VERSION "highnoon_telemetry"

NS_ :

BS_:

BU_: TPEE_MPPT_C TPEE_MPPT_B TPEE_MPPT_A Telemetry Pump Pedals PDU LV_Carrier External Dashboard_Display BPS ChargerInterface Controls VCU Bosch_LWS Prohelion_WaveSculptor22 Vector__XXX

CM_ "Full HighNoon telemetry catalog: CarCAN + SteeringCAN + MotorCAN + telem_rev1 (DAQ/GPS).";
CM_ "TelemCAN messages use internal ID 0x1000 | physical 11-bit CAN ID.";

CM_ "source=CarCAN" BO_ 1;
BO_ 1 BPS_Status: 8 BPS
SG_ BPS_Fault : 0|8@1+ (1,0) [0|0] "" Vector__XXX
SG_ BPS_Charge_OK : 8|1@1+ (1,0) [0|0] "" Vector__XXX
SG_ BPS_Regen_OK : 9|1@1+ (1,0) [0|0] "" Vector__XXX
SG_ HV_Plus_Contactor_State : 10|1@1+ (1,0) [0|0] "" Vector__XXX
SG_ HV_Minus_Contactor_State : 11|1@1+ (1,0) [0|0] "" Vector__XXX
SG_ Array_Contactor_State : 12|1@1+ (1,0) [0|0] "" Vector__XXX
SG_ Array_Precharge_Contactor_State : 13|1@1+ (1,0) [0|0] "" Vector__XXX
SG_ Main_Battery_Voltage : 16|24@1+ (0.001,0) [0|16777.215] "V" Vector__XXX
SG_ Main_Battery_Avg_Temperature : 40|16@1- (0.01,0) [-327.68|327.67] "°C" Vector__XXX
SG_ BPS_Segment0_Status : 56|1@1+ (1,0) [0|0] "" Vector__XXX
SG_ BPS_Segment1_Status : 57|1@1+ (1,0) [0|0] "" Vector__XXX
SG_ BPS_Segment2_Status : 58|1@1+ (1,0) [0|0] "" Vector__XXX
SG_ BPS_Segment3_Status : 59|1@1+ (1,0) [0|0] "" Vector__XXX
SG_ BPS_Segment4_Status : 60|1@1+ (1,0) [0|0] "" Vector__XXX
SG_ BPS_Segment5_Status : 61|1@1+ (1,0) [0|0] "" Vector__XXX
SG_ BPS_Segment6_Status : 62|1@1+ (1,0) [0|0] "" Vector__XXX
SG_ BPS_Segment7_Status : 63|1@1+ (1,0) [0|0] "" Vector__XXX

CM_ "source=CarCAN" BO_ 11;
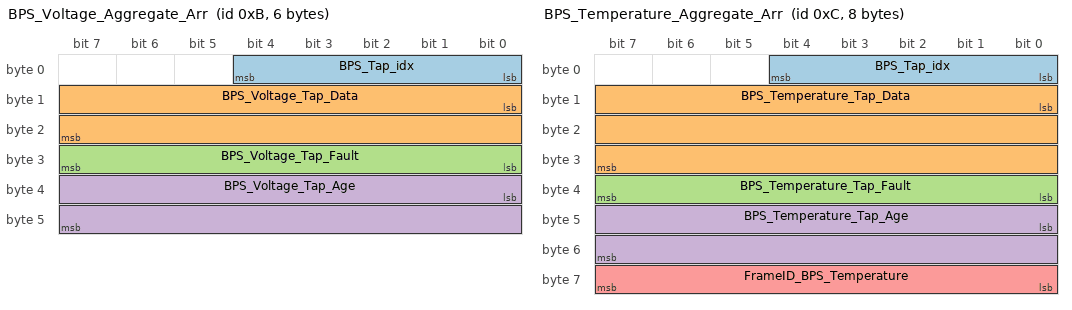
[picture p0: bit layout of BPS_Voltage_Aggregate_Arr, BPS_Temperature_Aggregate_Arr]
BO_ 11 BPS_Voltage_Aggregate_Arr: 6 BPS
SG_ BPS_Tap_idx : 0|5@1+ (1,0) [0|31] "" Vector__XXX
SG_ BPS_Voltage_Tap_Data : 8|16@1+ (0.001,0) [0|65.535] "V" Vector__XXX
SG_ BPS_Voltage_Tap_Fault : 24|8@1+ (1,0) [0|0] "" Vector__XXX
SG_ BPS_Voltage_Tap_Age : 32|16@1+ (1,0) [0|65535] "ms" Vector__XXX

CM_ "source=CarCAN" BO_ 12;
BO_ 12 BPS_Temperature_Aggregate_Arr: 8 BPS
SG_ BPS_Tap_idx : 0|5@1+ (1,0) [0|31] "" Vector__XXX
SG_ BPS_Temperature_Tap_Data : 8|24@1- (0.001,0) [-8388.608|8388.607] "°C" Vector__XXX
SG_ BPS_Temperature_Tap_Fault : 32|8@1+ (1,0) [0|255] "" Vector__XXX
SG_ BPS_Temperature_Tap_Age : 40|16@1+ (1,0) [0|65535] "ms" Vector__XXX
SG_ FrameID_BPS_Temperature : 56|8@1+ (1,0) [0|255] "" Vector__XXX

CM_ "source=CarCAN" BO_ 14;
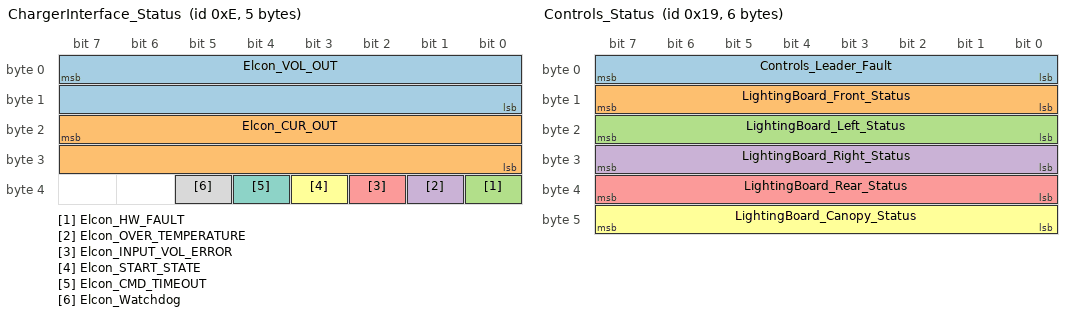
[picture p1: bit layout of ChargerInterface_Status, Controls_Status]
BO_ 14 ChargerInterface_Status: 5 ChargerInterface
SG_ Elcon_VOL_OUT : 7|16@0+ (0.1,0) [0|6553.5] "V" Vector__XXX
SG_ Elcon_CUR_OUT : 23|16@0+ (0.1,0) [0|6553.5] "A" Vector__XXX
SG_ Elcon_HW_FAULT : 32|1@0+ (1,0) [0|1] "" Vector__XXX
SG_ Elcon_OVER_TEMPERATURE : 33|1@0+ (1,0) [0|1] "" Vector__XXX
SG_ Elcon_INPUT_VOL_ERROR : 34|1@0+ (1,0) [0|1] "" Vector__XXX
SG_ Elcon_START_STATE : 35|1@0+ (1,0) [0|1] "" Vector__XXX
SG_ Elcon_CMD_TIMEOUT : 36|1@0+ (1,0) [0|1] "" Vector__XXX
SG_ Elcon_Watchdog : 37|1@0+ (1,0) [0|1] "" Vector__XXX

CM_ "source=CarCAN" BO_ 15;
BO_ 15 BPS_Fault_Val_Arr: 6 BPS
SG_ BPS_Tap_idx : 0|5@1+ (1,0) [0|31] "" Vector__XXX
SG_ BPS_Voltage_Tap_Data : 8|16@1+ (0.001,0) [0|65.535] "V" Vector__XXX
SG_ BPS_Temperature_Tap_Data : 24|24@1- (0.001,0) [-8388.608|8388.607] "°C" Vector__XXX

CM_ "source=CarCAN" BO_ 24;
BO_ 24 VCU_Status: 6 VCU
SG_ VCU_FSM_State : 0|4@1+ (1,0) [0|15] "" Vector__XXX
SG_ Motor_Ready : 4|1@1+ (1,0) [0|0] "" Vector__XXX
SG_ Motor_Precharge_Contactor_State : 5|1@1+ (1,0) [0|0] "" Vector__XXX
SG_ Motor_Contactor_State : 6|1@1+ (1,0) [0|0] "" Vector__XXX
SG_ VCU_Driver_Input_Watchdog : 7|1@1+ (1,0) [0|0] "" Vector__XXX
SG_ VCU_Pedals_Watchdog : 8|1@1+ (1,0) [0|0] "" Vector__XXX
SG_ VCU_BPS_Watchdog : 9|1@1+ (1,0) [0|0] "" Vector__XXX
SG_ VCU_Steering_Angle_Watchdog : 10|1@1+ (1,0) [0|1] "" Vector__XXX
SG_ VCU_BPS_FAULT_DETECTED : 11|1@1+ (1,0) [0|1] "" Vector__XXX
SG_ VCU_CONTROLS_FAULT_DETECTED : 12|1@1+ (1,0) [0|1] "" Vector__XXX
SG_ VCU_MTR_FAULT_DETECTED : 13|1@1+ (1,0) [0|1] "" Vector__XXX
SG_ VCU_PEDALS_FAULT_DETECTED : 14|1@1+ (1,0) [0|1] "" Vector__XXX
SG_ VCU_STEERING_FAULT_DETECTED : 15|1@1+ (1,0) [0|1] "" Vector__XXX
SG_ VCU_MotorCommandSource : 16|1@1+ (1,0) [0|1] "" Vector__XXX
SG_ VCU_Regen_Active : 17|1@1+ (1,0) [0|0] "" Vector__XXX
SG_ VCU_Regen_OK : 18|1@1+ (1,0) [0|0] "" Vector__XXX
SG_ VCU_MTR_PCHG_TIMEOUT : 19|1@1+ (1,0) [0|1] "" Vector__XXX
SG_ VCU_MTR_PCHG_CONT_TIMEOUT : 20|1@1+ (1,0) [0|1] "" Vector__XXX
SG_ VCU_MTR_PCHG_CONT_MISMATCH : 21|1@1+ (1,0) [0|1] "" Vector__XXX
SG_ VCU_MTR_CONT_MISMATCH : 22|1@1+ (1,0) [0|1] "" Vector__XXX
SG_ VCU_MTR_CONT_TIMEOUT : 23|1@1+ (1,0) [0|1] "" Vector__XXX
SG_ VCU_PCHG_OV : 24|1@1+ (1,0) [0|1] "" Vector__XXX
SG_ VCU_PCHG_UV : 25|1@1+ (1,0) [0|1] "" Vector__XXX
SG_ VCU_MTR_OV : 26|1@1+ (1,0) [0|1] "" Vector__XXX
SG_ VCU_MTR_UV : 27|1@1+ (1,0) [0|1] "" Vector__XXX
SG_ VCU_OTHER_FAULT : 28|1@1+ (1,0) [0|1] "" Vector__XXX
SG_ VCU_MTR_DIR_CHANGE_LOCKOUT : 29|1@1+ (1,0) [0|1] "" Vector__XXX
SG_ VCU_TIPPING_WARNING : 30|1@1+ (1,0) [0|1] "" Vector__XXX
SG_ VCU_WARN_REGEN_NOT_ALLOW : 31|1@1+ (1,0) [0|1] "" Vector__XXX
SG_ VCU_WARN_REGEN_NOT_EN : 32|1@1+ (1,0) [0|1] "" Vector__XXX
SG_ VCU_FSM_INP_BRAKE : 33|1@1+ (1,0) [0|1] "" Vector__XXX
SG_ VCU_FSM_INP_PCHG_OK : 34|1@1+ (1,0) [0|1] "" Vector__XXX
SG_ VCU_FSM_INP_CRUISE_REQ : 35|1@1+ (1,0) [0|1] "" Vector__XXX
SG_ VCU_FSM_INP_REGEN_REQ : 36|1@1+ (1,0) [0|1] "" Vector__XXX
SG_ VCU_FSM_INP_REGEN_ENABLE : 37|1@1+ (1,0) [0|1] "" Vector__XXX
SG_ VCU_FSM_INP_REGEN_RDY : 38|1@1+ (1,0) [0|1] "" Vector__XXX
SG_ VCU_FSM_INP_FORWARD : 39|1@1+ (1,0) [0|1] "" Vector__XXX
SG_ VCU_FSM_INP_NEUTRAL : 40|1@1+ (1,0) [0|1] "" Vector__XXX
SG_ VCU_FSM_INP_REVERSE : 41|1@1+ (1,0) [0|1] "" Vector__XXX

CM_ "source=CarCAN" BO_ 25;
BO_ 25 Controls_Status: 6 Controls
SG_ Controls_Leader_Fault : 0|8@1+ (1,0) [0|0] "" Vector__XXX
SG_ LightingBoard_Front_Status : 8|8@1+ (1,0) [0|0] "" Vector__XXX
SG_ LightingBoard_Left_Status : 16|8@1+ (1,0) [0|0] "" Vector__XXX
SG_ LightingBoard_Right_Status : 24|8@1+ (1,0) [0|0] "" Vector__XXX
SG_ LightingBoard_Rear_Status : 32|8@1+ (1,0) [0|0] "" Vector__XXX
SG_ LightingBoard_Canopy_Status : 40|8@1+ (1,0) [0|0] "" Vector__XXX

CM_ "source=CarCAN" BO_ 32;
BO_ 32 BPS_Precharge_Voltages: 6 BPS
SG_ BPS_Precharge_Battery_Voltage : 0|24@1+ (0.001,0) [0|16777.215] "V" Vector__XXX
SG_ BPS_Precharge_Array_Voltage : 24|24@1+ (0.001,0) [0|16777.215] "V" Vector__XXX

CM_ "source=CarCAN" BO_ 33;
BO_ 33 VCU_Precharge_Voltages: 6 VCU
SG_ VCU_Precharge_Battery_Voltage : 0|24@1+ (0.001,0) [0|16777.215] "V" Vector__XXX
SG_ VCU_Precharge_Motor_Voltage : 24|24@1+ (0.001,0) [0|16777.215] "V" Vector__XXX

CM_ "source=CarCAN" BO_ 80;
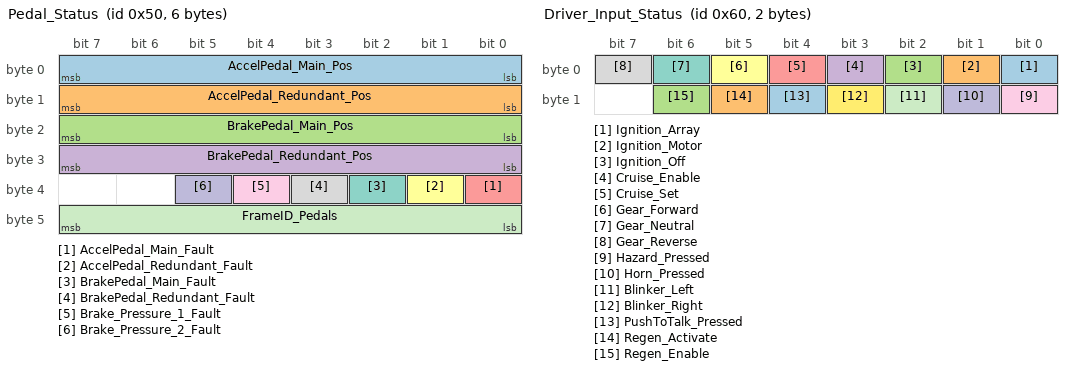
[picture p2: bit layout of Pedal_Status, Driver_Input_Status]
BO_ 80 Pedal_Status: 6 Pedals
SG_ AccelPedal_Main_Pos : 0|8@1+ (1,0) [0|100] "%"  VCU
SG_ AccelPedal_Redundant_Pos : 8|8@1+ (1,0) [0|100] "%"  VCU
SG_ BrakePedal_Main_Pos : 16|8@1+ (1,0) [0|100] "%"  VCU
SG_ BrakePedal_Redundant_Pos : 24|8@1+ (1,0) [0|100] "%"  VCU
SG_ AccelPedal_Main_Fault : 32|1@1+ (1,0) [0|0] ""  VCU
SG_ AccelPedal_Redundant_Fault : 33|1@1+ (1,0) [0|0] ""  VCU
SG_ BrakePedal_Main_Fault : 34|1@1+ (1,0) [0|0] ""  VCU
SG_ BrakePedal_Redundant_Fault : 35|1@1+ (1,0) [0|0] ""  VCU
SG_ Brake_Pressure_1_Fault : 36|1@1+ (1,0) [0|0] "" Vector__XXX
SG_ Brake_Pressure_2_Fault : 37|1@1+ (1,0) [0|0] "" Vector__XXX
SG_ FrameID_Pedals : 40|8@1+ (1,0) [0|255] "" Vector__XXX

CM_ "source=CarCAN" BO_ 96;
BO_ 96 Driver_Input_Status: 2 Controls
SG_ Ignition_Array : 0|1@1+ (1,0) [0|0] ""  VCU
SG_ Ignition_Motor : 1|1@1+ (1,0) [0|0] ""  VCU
SG_ Ignition_Off : 2|1@1+ (1,0) [0|0] ""  VCU
SG_ Cruise_Enable : 3|1@1+ (1,0) [0|0] ""  VCU
SG_ Cruise_Set : 4|1@1+ (1,0) [0|0] ""  VCU
SG_ Gear_Forward : 5|1@1+ (1,0) [0|0] ""  VCU
SG_ Gear_Neutral : 6|1@1+ (1,0) [0|0] ""  VCU
SG_ Gear_Reverse : 7|1@1+ (1,0) [0|0] ""  VCU
SG_ Hazard_Pressed : 8|1@1+ (1,0) [0|0] "" Vector__XXX
SG_ Horn_Pressed : 9|1@1+ (1,0) [0|0] "" Vector__XXX
SG_ Blinker_Left : 10|1@1+ (1,0) [0|0] "" Vector__XXX
SG_ Blinker_Right : 11|1@1+ (1,0) [0|0] "" Vector__XXX
SG_ PushToTalk_Pressed : 12|1@1+ (1,0) [0|0] "" Vector__XXX
SG_ Regen_Activate : 13|1@1+ (1,0) [0|0] ""  VCU
SG_ Regen_Enable : 14|1@1+ (1,0) [0|0] ""  VCU

CM_ "source=CarCAN" BO_ 103;
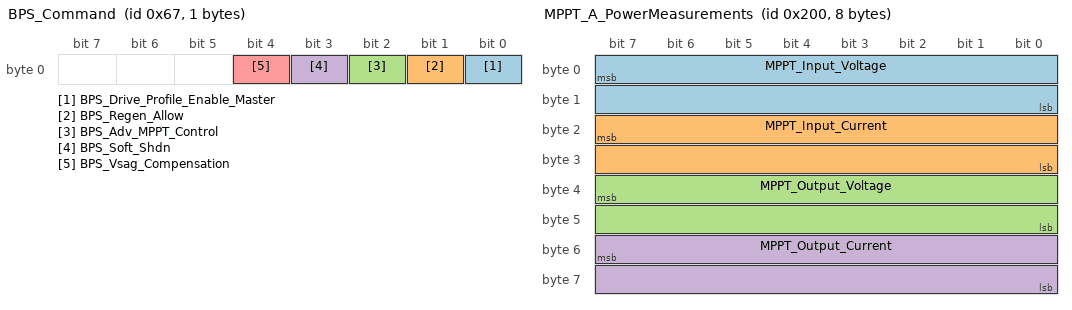
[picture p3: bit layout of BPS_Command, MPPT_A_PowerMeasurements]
BO_ 103 BPS_Command: 1 Controls
SG_ BPS_Drive_Profile_Enable_Master : 0|1@1+ (1,0) [0|1] "" Vector__XXX
SG_ BPS_Regen_Allow : 1|1@1+ (1,0) [0|1] "" Vector__XXX
SG_ BPS_Adv_MPPT_Control : 2|1@1+ (1,0) [0|1] "" Vector__XXX
SG_ BPS_Soft_Shdn : 3|1@1+ (1,0) [0|1] "" Vector__XXX
SG_ BPS_Vsag_Compensation : 4|1@1+ (1,0) [0|1] "" Vector__XXX

CM_ "source=CarCAN" BO_ 105;
BO_ 105 BPS_Module_Override: 8 Controls
SG_ Module0_Override : 0|2@1+ (1,0) [0|3] "" Vector__XXX
SG_ Module1_Override : 2|2@1+ (1,0) [0|3] "" Vector__XXX
SG_ Module2_Override : 4|2@1+ (1,0) [0|3] "" Vector__XXX
SG_ Module3_Override : 6|2@1+ (1,0) [0|3] "" Vector__XXX
SG_ Module4_Override : 8|2@1+ (1,0) [0|3] "" Vector__XXX
SG_ Module5_Override : 10|2@1+ (1,0) [0|3] "" Vector__XXX
SG_ Module6_Override : 12|2@1+ (1,0) [0|3] "" Vector__XXX
SG_ Module7_Override : 14|2@1+ (1,0) [0|3] "" Vector__XXX
SG_ Module8_Override : 16|2@1+ (1,0) [0|3] "" Vector__XXX
SG_ Module9_Override : 18|2@1+ (1,0) [0|3] "" Vector__XXX
SG_ Module10_Override : 20|2@1+ (1,0) [0|3] "" Vector__XXX
SG_ Module11_Override : 22|2@1+ (1,0) [0|3] "" Vector__XXX
SG_ Module12_Override : 24|2@1+ (1,0) [0|3] "" Vector__XXX
SG_ Module13_Override : 26|2@1+ (1,0) [0|3] "" Vector__XXX
SG_ Module14_Override : 28|2@1+ (1,0) [0|3] "" Vector__XXX
SG_ Module15_Override : 30|2@1+ (1,0) [0|3] "" Vector__XXX
SG_ Module16_Override : 32|2@1+ (1,0) [0|3] "" Vector__XXX
SG_ Module17_Override : 34|2@1+ (1,0) [0|3] "" Vector__XXX
SG_ Module18_Override : 36|2@1+ (1,0) [0|3] "" Vector__XXX
SG_ Module19_Override : 38|2@1+ (1,0) [0|3] "" Vector__XXX
SG_ Module20_Override : 40|2@1+ (1,0) [0|3] "" Vector__XXX
SG_ Module21_Override : 42|2@1+ (1,0) [0|3] "" Vector__XXX
SG_ Module22_Override : 44|2@1+ (1,0) [0|3] "" Vector__XXX
SG_ Module23_Override : 46|2@1+ (1,0) [0|3] "" Vector__XXX
SG_ Module24_Override : 48|2@1+ (1,0) [0|3] "" Vector__XXX
SG_ Module25_Override : 50|2@1+ (1,0) [0|3] "" Vector__XXX
SG_ Module26_Override : 52|2@1+ (1,0) [0|3] "" Vector__XXX
SG_ Module27_Override : 54|2@1+ (1,0) [0|3] "" Vector__XXX
SG_ Module28_Override : 56|2@1+ (1,0) [0|3] "" Vector__XXX
SG_ Module29_Override : 58|2@1+ (1,0) [0|3] "" Vector__XXX
SG_ Module30_Override : 60|2@1+ (1,0) [0|3] "" Vector__XXX
SG_ Module31_Override : 62|2@1+ (1,0) [0|3] "" Vector__XXX

CM_ "source=CarCAN" BO_ 512;
BO_ 512 MPPT_A_PowerMeasurements: 8 TPEE_MPPT_A
SG_ MPPT_Input_Voltage : 7|16@0- (0.01,0) [-327.68|327.67] "V" Vector__XXX
SG_ MPPT_Input_Current : 23|16@0- (0.0005,0) [-16.384|16.3835] "A" Vector__XXX
SG_ MPPT_Output_Voltage : 39|16@0- (0.01,0) [-327.68|327.67] "V" Vector__XXX
SG_ MPPT_Output_Current : 55|16@0- (0.0005,0) [-16.384|16.3835] "A" Vector__XXX

CM_ "source=CarCAN" BO_ 513;
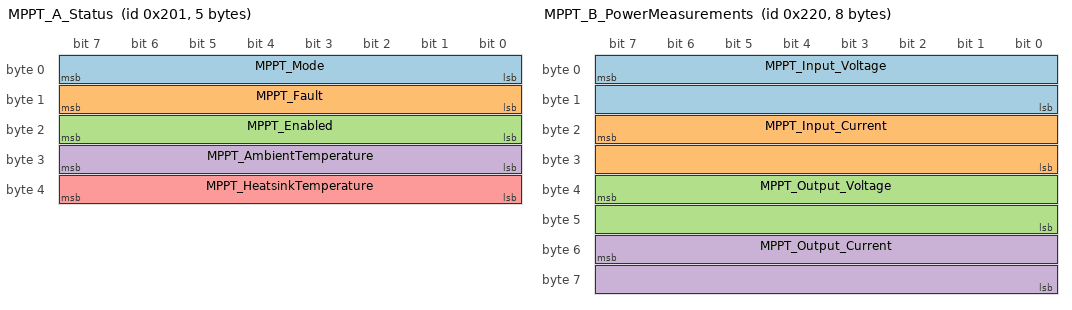
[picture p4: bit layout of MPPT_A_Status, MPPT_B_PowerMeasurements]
BO_ 513 MPPT_A_Status: 5 TPEE_MPPT_A
SG_ MPPT_Mode : 7|8@0+ (1,0) [0|0] "" Vector__XXX
SG_ MPPT_Fault : 15|8@0+ (1,0) [0|0] "" Vector__XXX
SG_ MPPT_Enabled : 23|8@0- (1,0) [0|2] "" Vector__XXX
SG_ MPPT_AmbientTemperature : 31|8@0- (1,0) [-128|127] "°C" Vector__XXX
SG_ MPPT_HeatsinkTemperature : 39|8@0- (1,0) [-128|127] "°C" Vector__XXX

CM_ "source=CarCAN" BO_ 514;
BO_ 514 MPPT_A_SweepMeasurements: 6 TPEE_MPPT_A
SG_ MPPT_Sweep_Data_cnt : 7|8@0+ (1,0) [0|127] "" Vector__XXX
SG_ MPPT_Sweep_Data_Current : 23|16@0- (0.0005,0) [-16.384|16.3835] "A" Vector__XXX
SG_ MPPT_Sweep_Data_Voltage : 39|16@0- (0.01,0) [-327.68|327.67] "V" Vector__XXX

CM_ "source=CarCAN" BO_ 521;
BO_ 521 MPPT_A_SetMode: 1 BPS
SG_ MPPT_Set_Enable : 7|8@0+ (1,0) [0|2] ""  TPEE_MPPT_A

CM_ "source=CarCAN" BO_ 528;
BO_ 528 MPPT_A_PerformSweep: 5 External
SG_ MPPT_Set_Sweep_Start : 7|16@0- (0.01,0) [-327.68|327.67] "V" Vector__XXX
SG_ MPPT_Set_Sweep_End : 23|16@0- (0.0005,0) [-16.384|16.3835] "A" Vector__XXX
SG_ MPPT_Set_Sweep_Size : 39|8@0+ (1,0) [4|128] "" Vector__XXX

CM_ "source=CarCAN" BO_ 529;
BO_ 529 MPPT_A_SetOutputVoltageLimit: 2 BPS
SG_ MPPT_SetOutputVoltageLimit : 7|16@0- (0.01,0) [-327.68|327.67] "V" Vector__XXX

CM_ "source=CarCAN" BO_ 530;
BO_ 530 MPPT_A_SetOutputCurrentLimit: 2 BPS
SG_ MPPT_SetOutputCurrentLimit : 7|16@0- (0.0005,0) [-16.384|16.3835] "A" Vector__XXX

CM_ "source=CarCAN" BO_ 544;
BO_ 544 MPPT_B_PowerMeasurements: 8 TPEE_MPPT_B
SG_ MPPT_Input_Voltage : 7|16@0- (0.01,0) [-327.68|327.67] "V" Vector__XXX
SG_ MPPT_Input_Current : 23|16@0- (0.0005,0) [-16.384|16.3835] "A" Vector__XXX
SG_ MPPT_Output_Voltage : 39|16@0- (0.01,0) [-327.68|327.67] "V" Vector__XXX
SG_ MPPT_Output_Current : 55|16@0- (0.0005,0) [-16.384|16.3835] "A" Vector__XXX

CM_ "source=CarCAN" BO_ 545;
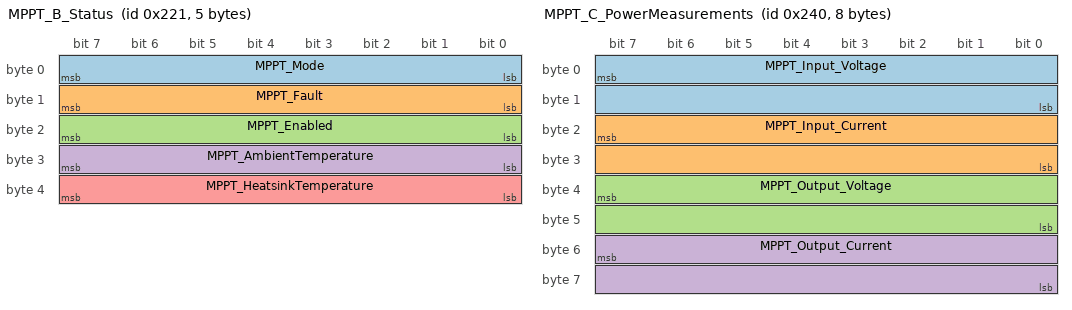
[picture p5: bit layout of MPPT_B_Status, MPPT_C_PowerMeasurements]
BO_ 545 MPPT_B_Status: 5 TPEE_MPPT_B
SG_ MPPT_Mode : 7|8@0+ (1,0) [0|0] "" Vector__XXX
SG_ MPPT_Fault : 15|8@0+ (1,0) [0|0] "" Vector__XXX
SG_ MPPT_Enabled : 23|8@0- (1,0) [0|2] "" Vector__XXX
SG_ MPPT_AmbientTemperature : 31|8@0- (1,0) [-128|127] "°C" Vector__XXX
SG_ MPPT_HeatsinkTemperature : 39|8@0- (1,0) [-128|127] "°C" Vector__XXX

CM_ "source=CarCAN" BO_ 546;
BO_ 546 MPPT_B_SweepMeasurements: 6 TPEE_MPPT_B
SG_ MPPT_Sweep_Data_cnt : 7|8@0+ (1,0) [0|127] "" Vector__XXX
SG_ MPPT_Sweep_Data_Current : 23|16@0- (0.0005,0) [-16.384|16.3835] "A" Vector__XXX
SG_ MPPT_Sweep_Data_Voltage : 39|16@0- (0.01,0) [-327.68|327.67] "V" Vector__XXX

CM_ "source=CarCAN" BO_ 553;
BO_ 553 MPPT_B_SetMode: 1 BPS
SG_ MPPT_Set_Enable : 7|8@0+ (1,0) [0|2] "" Vector__XXX

CM_ "source=CarCAN" BO_ 560;
BO_ 560 MPPT_B_PerformSweep: 5 External
SG_ MPPT_Set_Sweep_Start : 7|16@0- (0.01,0) [-327.68|327.67] "V" Vector__XXX
SG_ MPPT_Set_Sweep_End : 23|16@0- (0.0005,0) [-16.384|16.3835] "A" Vector__XXX
SG_ MPPT_Set_Sweep_Size : 39|8@0+ (1,0) [4|128] "" Vector__XXX

CM_ "source=CarCAN" BO_ 561;
BO_ 561 MPPT_B_SetOutputVoltageLimit: 2 BPS
SG_ MPPT_SetOutputVoltageLimit : 7|16@0- (0.01,0) [-327.68|327.67] "V" Vector__XXX

CM_ "source=CarCAN" BO_ 562;
BO_ 562 MPPT_B_SetOutputCurrentLimit: 2 BPS
SG_ MPPT_SetOutputCurrentLimit : 7|16@0- (0.0005,0) [-16.384|16.3835] "A" Vector__XXX

CM_ "source=CarCAN" BO_ 576;
BO_ 576 MPPT_C_PowerMeasurements: 8 TPEE_MPPT_C
SG_ MPPT_Input_Voltage : 7|16@0- (0.01,0) [-327.68|327.67] "V" Vector__XXX
SG_ MPPT_Input_Current : 23|16@0- (0.0005,0) [-16.384|16.3835] "A" Vector__XXX
SG_ MPPT_Output_Voltage : 39|16@0- (0.01,0) [-327.68|327.67] "V" Vector__XXX
SG_ MPPT_Output_Current : 55|16@0- (0.0005,0) [-16.384|16.3835] "A" Vector__XXX

CM_ "source=CarCAN" BO_ 577;
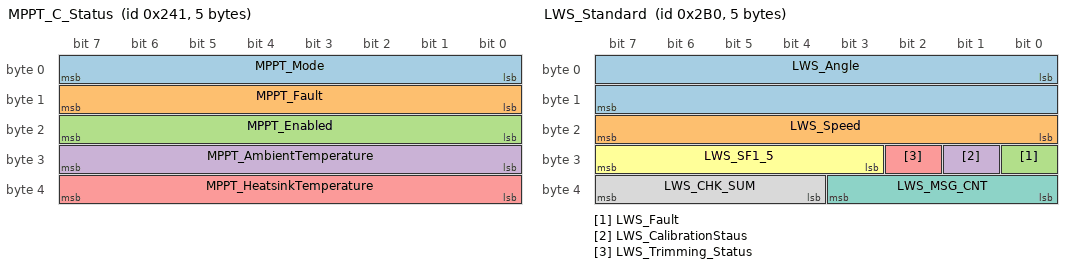
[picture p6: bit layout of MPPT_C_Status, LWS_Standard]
BO_ 577 MPPT_C_Status: 5 TPEE_MPPT_C
SG_ MPPT_Mode : 7|8@0+ (1,0) [0|0] "" Vector__XXX
SG_ MPPT_Fault : 15|8@0+ (1,0) [0|0] "" Vector__XXX
SG_ MPPT_Enabled : 23|8@0- (1,0) [0|2] "" Vector__XXX
SG_ MPPT_AmbientTemperature : 31|8@0- (1,0) [-128|127] "°C" Vector__XXX
SG_ MPPT_HeatsinkTemperature : 39|8@0- (1,0) [-128|127] "°C" Vector__XXX

CM_ "source=CarCAN" BO_ 578;
BO_ 578 MPPT_C_SweepMeasurements: 6 TPEE_MPPT_C
SG_ MPPT_Sweep_Data_cnt : 7|8@0+ (1,0) [0|127] "" Vector__XXX
SG_ MPPT_Sweep_Data_Current : 23|16@0- (0.0005,0) [-16.384|16.3835] "A" Vector__XXX
SG_ MPPT_Sweep_Data_Voltage : 39|16@0- (0.01,0) [-327.68|327.67] "V" Vector__XXX

CM_ "source=CarCAN" BO_ 585;
BO_ 585 MPPT_C_SetMode: 1 BPS
SG_ MPPT_Set_Enable : 7|8@0+ (1,0) [0|2] "" Vector__XXX

CM_ "source=CarCAN" BO_ 592;
BO_ 592 MPPT_C_PerformSweep: 5 External
SG_ MPPT_Set_Sweep_Start : 7|16@0- (0.01,0) [-327.68|327.67] "V" Vector__XXX
SG_ MPPT_Set_Sweep_End : 23|16@0- (0.0005,0) [-16.384|16.3835] "A" Vector__XXX
SG_ MPPT_Set_Sweep_Size : 39|8@0+ (1,0) [4|128] "" Vector__XXX

CM_ "source=CarCAN" BO_ 593;
BO_ 593 MPPT_C_SetOutputVoltageLimit: 2 BPS
SG_ MPPT_SetOutputVoltageLimit : 7|16@0- (0.01,0) [-327.68|327.67] "V" Vector__XXX

CM_ "source=CarCAN" BO_ 594;
BO_ 594 MPPT_C_SetOutputCurrentLimit: 2 BPS
SG_ MPPT_SetOutputCurrentLimit : 7|16@0- (0.0005,0) [-16.384|16.3835] "A" Vector__XXX

CM_ "source=SteeringCAN" BO_ 688;
BO_ 688 LWS_Standard: 5 Bosch_LWS
SG_ LWS_Angle : 0|16@1- (0.1,0) [-780|780] "°" Vector__XXX
SG_ LWS_Speed : 16|8@1+ (4,0) [0|1016] "°/s" Vector__XXX
SG_ LWS_Fault : 24|1@1+ (1,0) [0|1] "" Vector__XXX
SG_ LWS_CalibrationStaus : 25|1@1+ (1,0) [0|1] "" Vector__XXX
SG_ LWS_Trimming_Status : 26|1@1+ (1,0) [0|1] "" Vector__XXX
SG_ LWS_SF1_5 : 27|5@1+ (1,0) [0|31] "" Vector__XXX
SG_ LWS_MSG_CNT : 32|4@1+ (1,0) [0|15] "" Vector__XXX
SG_ LWS_CHK_SUM : 36|4@1+ (1,0) [0|15] "" Vector__XXX

CM_ "source=CarCAN" BO_ 768;
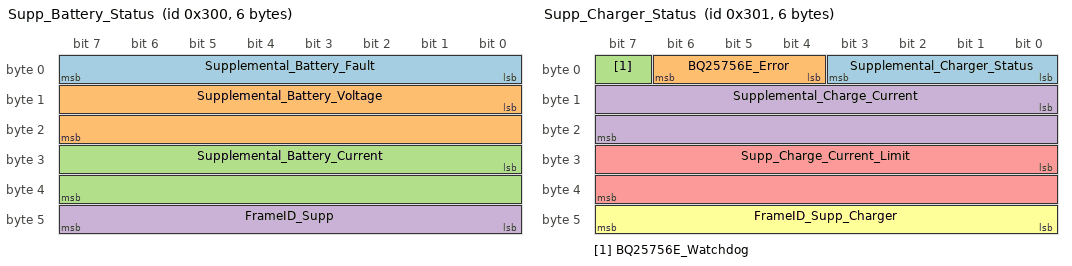
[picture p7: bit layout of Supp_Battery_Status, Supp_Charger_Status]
BO_ 768 Supp_Battery_Status: 6 LV_Carrier
SG_ Supplemental_Battery_Fault : 0|8@1+ (1,0) [0|255] "" Vector__XXX
SG_ Supplemental_Battery_Voltage : 8|16@1+ (0.001,0) [0|30] "V" Vector__XXX
SG_ Supplemental_Battery_Current : 24|16@1- (0.001,0) [-32.768|32.767] "A" Vector__XXX
SG_ FrameID_Supp : 40|8@1+ (1,0) [0|255] "" Vector__XXX

CM_ "source=CarCAN" BO_ 769;
BO_ 769 Supp_Charger_Status: 6 LV_Carrier
SG_ Supplemental_Charger_Status : 0|4@1+ (1,0) [0|15] "" Vector__XXX
SG_ BQ25756E_Error : 4|3@1+ (1,0) [0|7] "" Vector__XXX
SG_ BQ25756E_Watchdog : 7|1@1+ (1,0) [0|1] "" Vector__XXX
SG_ Supplemental_Charge_Current : 8|16@1- (0.001,0) [-32.768|32.767] "A" Vector__XXX
SG_ Supp_Charge_Current_Limit : 24|16@1+ (1,0) [0|65535] "mA" Vector__XXX
SG_ FrameID_Supp_Charger : 40|8@1+ (1,0) [0|255] "" Vector__XXX

CM_ "source=CarCAN" BO_ 770;
BO_ 770 Supp_Vicor_Stats: 5 LV_Carrier
SG_ Supplemental_Vicor_Voltage : 0|16@1+ (0.001,0) [0|65.535] "V" Vector__XXX
SG_ Supplemental_Vicor_Current : 16|16@1- (0.001,0) [-32.768|32.767] "A" Vector__XXX
SG_ FrameID_Supp_Charger : 32|8@1+ (1,0) [0|255] "" Vector__XXX

CM_ "source=CarCAN" BO_ 848;
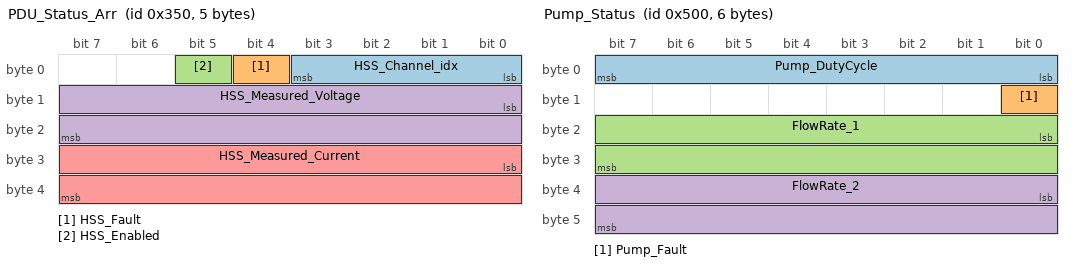
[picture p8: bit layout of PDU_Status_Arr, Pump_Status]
BO_ 848 PDU_Status_Arr: 5 PDU
SG_ HSS_Channel_idx : 0|4@1+ (1,0) [0|16] "" Vector__XXX
SG_ HSS_Fault : 4|1@1+ (1,0) [0|0] "" Vector__XXX
SG_ HSS_Enabled : 5|1@1+ (1,0) [0|0] "" Vector__XXX
SG_ HSS_Measured_Voltage : 8|16@1+ (0.001,0) [0|65.535] "V" Vector__XXX
SG_ HSS_Measured_Current : 24|16@1+ (0.001,0) [0|65.535] "A" Vector__XXX

CM_ "source=CarCAN" BO_ 849;
BO_ 849 PDU_Set_Switch_Arr: 1 VCU
SG_ HSS_Channel_idx : 0|4@1+ (1,0) [0|16] "" Vector__XXX
SG_ HSS_SetSwitch : 4|2@1+ (1,0) [0|0] ""  PDU

CM_ "source=CarCAN" BO_ 850;
BO_ 850 PDU_Set_Current_Limit_Arr: 3 VCU
SG_ HSS_Channel_idx : 0|4@1+ (1,0) [0|16] "" Vector__XXX
SG_ HSS_Current_Limit : 8|16@1+ (0.001,0) [0|8] "A"  PDU

CM_ "source=MotorCAN" BO_ 1025;
BO_ 1025 MC_DriveCommand: 8 VCU
SG_ MC_MotorVelocitySetpoint : 0|32@1- (1,0) [0|12000] "rpm"  Prohelion_WaveSculptor22
SG_ MC_MotorCurrentSetpoint : 32|32@1- (1,0) [0|1] "%"  Prohelion_WaveSculptor22

CM_ "source=MotorCAN" BO_ 1026;
BO_ 1026 MC_PowerCommand: 4 VCU
SG_ MC_MotorPowerSetpoint : 0|32@1- (1,0) [0|1] "%"  Prohelion_WaveSculptor22

CM_ "source=MotorCAN" BO_ 1027;
BO_ 1027 MC_ResetCommand: 1 VCU
SG_ MC_Reset : 0|8@1+ (1,0) [0|0] "" Vector__XXX

CM_ "source=MotorCAN" BO_ 1056;
BO_ 1056 MC_Info: 8 Prohelion_WaveSculptor22
SG_ MC_TritiumID : 0|32@1+ (1,0) [0|0] "" Vector__XXX
SG_ MC_SerialNumber : 32|32@1+ (1,0) [0|0] "" Vector__XXX

CM_ "source=MotorCAN" BO_ 1057;
BO_ 1057 MC_Status: 8 Prohelion_WaveSculptor22
SG_ MC_LIMIT_OutputVoltagePWM : 0|1@1+ (1,0) [0|1] "" Vector__XXX
SG_ MC_LIMIT_MotorCurrent : 1|1@1+ (1,0) [0|1] "" Vector__XXX
SG_ MC_LIMIT_Velocity : 2|1@1+ (1,0) [0|1] "" Vector__XXX
SG_ MC_LIMIT_BusCurrent : 3|1@1+ (1,0) [0|1] "" Vector__XXX
SG_ MC_LIMIT_BusVoltageUpper : 4|1@1+ (1,0) [0|1] "" Vector__XXX
SG_ MC_LIMIT_BusVoltageLower : 5|1@1+ (1,0) [0|1] "" Vector__XXX
SG_ MC_LIMIT_MotorTemp : 6|1@1+ (1,0) [0|1] "" Vector__XXX
SG_ MC_LIMIT_Reserved : 7|9@1+ (1,0) [0|511] "" Vector__XXX
SG_ MC_FAULT_HardwareOverCurrent : 16|1@1+ (1,0) [0|1] "" Vector__XXX
SG_ MC_FAULT_SoftwareOverCurrent : 17|1@1+ (1,0) [0|1] "" Vector__XXX
SG_ MC_FAULT_DcBusOverVoltage : 18|1@1+ (1,0) [0|1] "" Vector__XXX
SG_ MC_FAULT_BadMotorPositionHallSeq : 19|1@1+ (1,0) [0|1] "" Vector__XXX
SG_ MC_FAULT_WatchdogCausedLastReset : 20|1@1+ (1,0) [0|1] "" Vector__XXX
SG_ MC_FAULT_ConfigRead : 21|1@1+ (1,0) [0|1] "" Vector__XXX
SG_ MC_FAULT_15vRailUnderVoltage : 22|1@1+ (1,0) [0|1] "" Vector__XXX
SG_ MC_FAULT_DesaturationFault : 23|1@1+ (1,0) [0|1] "" Vector__XXX
SG_ MC_FAULT_MotorOverSpeed : 24|1@1+ (1,0) [0|1] "" Vector__XXX
SG_ MC_FAULT_Reserved : 25|7@1+ (1,0) [0|0] "" Vector__XXX
SG_ MC_ActiveMotor : 32|16@1+ (1,0) [0|0] "" Vector__XXX
SG_ MC_TxErrorCount : 48|8@1+ (1,0) [0|0] "" Vector__XXX
SG_ MC_RxErrorCount : 56|8@1+ (1,0) [0|0] "" Vector__XXX

CM_ "source=MotorCAN" BO_ 1058;
BO_ 1058 MC_BusMeasurement: 8 Prohelion_WaveSculptor22
SG_ MC_BusVoltage : 0|32@1- (1,0) [0|0] "V" Vector__XXX
SG_ MC_BusCurrent : 32|32@1- (1,0) [0|0] "A" Vector__XXX

CM_ "source=MotorCAN" BO_ 1059;
BO_ 1059 MC_VelocityMeasurement: 8 Prohelion_WaveSculptor22
SG_ MC_MotorVelocity : 0|32@1- (1,0) [0|0] "rpm" Vector__XXX
SG_ MC_VehicleVelocity : 32|32@1- (1,0) [0|0] "m/s" Vector__XXX

CM_ "source=MotorCAN" BO_ 1060;
BO_ 1060 MC_PhaseCurrentMeasurement: 8 Prohelion_WaveSculptor22
SG_ MC_PhaseCurrentB : 0|32@1- (1,0) [0|0] "A_rms" Vector__XXX
SG_ MC_PhaseCurrentC : 32|32@1- (1,0) [0|0] "A_rms" Vector__XXX

CM_ "source=MotorCAN" BO_ 1061;
BO_ 1061 MC_MotorVoltageVectorMeasurement: 8 Prohelion_WaveSculptor22
SG_ MC_Vq : 0|32@1- (1,0) [0|0] "V" Vector__XXX
SG_ MC_Vd : 32|32@1- (1,0) [0|0] "V" Vector__XXX

CM_ "source=MotorCAN" BO_ 1062;
BO_ 1062 MC_MotorCurrentVectorMeasurement: 8 Prohelion_WaveSculptor22
SG_ MC_Iq : 0|32@1- (1,0) [0|0] "A" Vector__XXX
SG_ MC_Id : 32|32@1- (1,0) [0|0] "A" Vector__XXX

CM_ "source=MotorCAN" BO_ 1063;
BO_ 1063 MC_BackEMFMeasurementPrediction: 8 Prohelion_WaveSculptor22
SG_ MC_BEMFq : 0|32@1- (1,0) [0|0] "V" Vector__XXX
SG_ MC_BEMFd : 32|32@1- (1,0) [0|0] "V" Vector__XXX

CM_ "source=MotorCAN" BO_ 1064;
BO_ 1064 MC_15V_RailMeasurement: 8 Prohelion_WaveSculptor22
SG_ MC_Supply15V : 32|32@1- (1,0) [0|0] "V" Vector__XXX

CM_ "source=MotorCAN" BO_ 1065;
BO_ 1065 MC_3V3_19V_RailMeasurement: 8 Prohelion_WaveSculptor22
SG_ MC_Supply1V9 : 0|32@1- (1,0) [0|0] "V" Vector__XXX
SG_ MC_Supply3V3 : 32|32@1- (1,0) [0|0] "V" Vector__XXX

CM_ "source=MotorCAN" BO_ 1067;
BO_ 1067 MC_Motor_TempMeasurement: 8 Prohelion_WaveSculptor22
SG_ MC_MotorTemp : 0|32@1- (1,0) [0|0] "°C" Vector__XXX
SG_ MC_HeatsinkTemp : 32|32@1- (1,0) [0|0] "°C" Vector__XXX

CM_ "source=MotorCAN" BO_ 1068;
BO_ 1068 MC_DspBoardTempMeasurement: 8 Prohelion_WaveSculptor22
SG_ MC_DspBoardTemp : 0|32@1- (1,0) [0|0] "°C" Vector__XXX

CM_ "source=MotorCAN" BO_ 1070;
BO_ 1070 MC_OdometerBusAhMeasurement: 8 Prohelion_WaveSculptor22
SG_ MC_TripOdometer : 0|32@1- (1,0) [0|0] "m" Vector__XXX
SG_ MC_DCBusAh : 32|32@1- (1,0) [0|0] "Ah" Vector__XXX

CM_ "source=MotorCAN" BO_ 1079;
BO_ 1079 MC_SlipSpeedMeasurement: 8 Prohelion_WaveSculptor22
SG_ MC_SlipSpeed : 0|32@1- (1,0) [0|0] "Hz" Vector__XXX

CM_ "source=CarCAN" BO_ 1280;
BO_ 1280 Pump_Status: 6 Pump
SG_ Pump_DutyCycle : 0|8@1+ (1,0) [0|100] "" Vector__XXX
SG_ Pump_Fault : 8|1@1+ (1,0) [0|0] "" Vector__XXX
SG_ FlowRate_1 : 16|16@1+ (0.001,0) [0|65.535] "L/min" Vector__XXX
SG_ FlowRate_2 : 32|16@1+ (0.001,0) [0|65.535] "L/min" Vector__XXX

CM_ "source=CarCAN" BO_ 1281;
BO_ 1281 Coolant_Temperature: 4 Pump
SG_ Coolant_Temperature_1 : 0|16@1- (0.01,0) [-327.68|327.67] "°C" Vector__XXX
SG_ Coolant_Temperature_2 : 16|16@1- (0.01,0) [-327.68|327.67] "°C" Vector__XXX

CM_ "source=CarCAN" BO_ 1282;
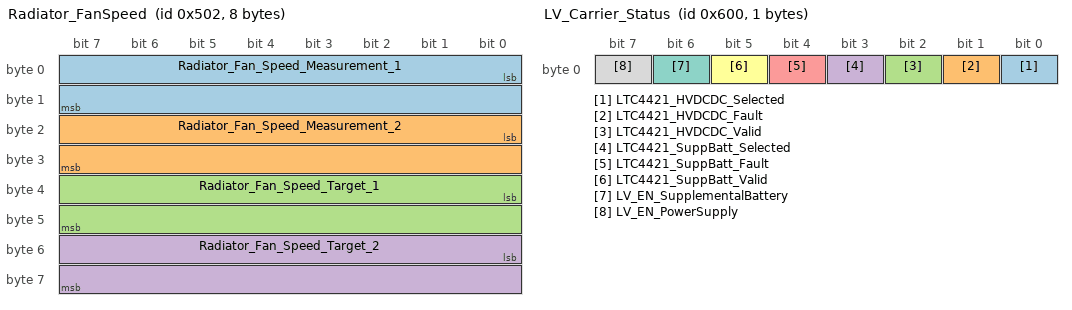
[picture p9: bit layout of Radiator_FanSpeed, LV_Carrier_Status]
BO_ 1282 Radiator_FanSpeed: 8 Pump
SG_ Radiator_Fan_Speed_Measurement_1 : 0|16@1+ (1,0) [0|65535] "rpm" Vector__XXX
SG_ Radiator_Fan_Speed_Measurement_2 : 16|16@1+ (1,0) [0|65535] "rpm" Vector__XXX
SG_ Radiator_Fan_Speed_Target_1 : 32|16@1+ (1,0) [0|65535] "rpm" Vector__XXX
SG_ Radiator_Fan_Speed_Target_2 : 48|16@1+ (1,0) [0|65535] "rpm" Vector__XXX

CM_ "source=CarCAN" BO_ 1536;
BO_ 1536 LV_Carrier_Status: 1 LV_Carrier
SG_ LTC4421_HVDCDC_Selected : 0|1@1+ (1,0) [0|1] "" Vector__XXX
SG_ LTC4421_HVDCDC_Fault : 1|1@1+ (1,0) [0|1] "" Vector__XXX
SG_ LTC4421_HVDCDC_Valid : 2|1@1+ (1,0) [0|1] "" Vector__XXX
SG_ LTC4421_SuppBatt_Selected : 3|1@1+ (1,0) [0|1] "" Vector__XXX
SG_ LTC4421_SuppBatt_Fault : 4|1@1+ (1,0) [0|1] "" Vector__XXX
SG_ LTC4421_SuppBatt_Valid : 5|1@1+ (1,0) [0|1] "" Vector__XXX
SG_ LV_EN_SupplementalBattery : 6|1@1+ (1,0) [0|1] "" Vector__XXX
SG_ LV_EN_PowerSupply : 7|1@1+ (1,0) [0|1] "" Vector__XXX

CM_ "source=CarCAN" BO_ 1616;
BO_ 1616 Brake_Pressure_1: 5 Pedals
SG_ Brake_Pressure : 0|16@1+ (0.1,0) [0|3000] "PSI"  VCU
SG_ Brake_Pressure_ADC : 16|12@1+ (1,0) [0|4095] ""  VCU
SG_ FrameID_Pedals : 32|8@1+ (1,0) [0|255] "" Vector__XXX

CM_ "source=CarCAN" BO_ 1617;
BO_ 1617 Brake_Pressure_2: 5 Pedals
SG_ Brake_Pressure : 0|16@1+ (0.1,0) [0|3000] "PSI" Vector__XXX
SG_ Brake_Pressure_ADC : 16|12@1+ (1,0) [0|4095] "" Vector__XXX
SG_ FrameID_Pedals : 32|8@1+ (1,0) [0|255] "" Vector__XXX

CM_ "source=CarCAN" BO_ 1639;
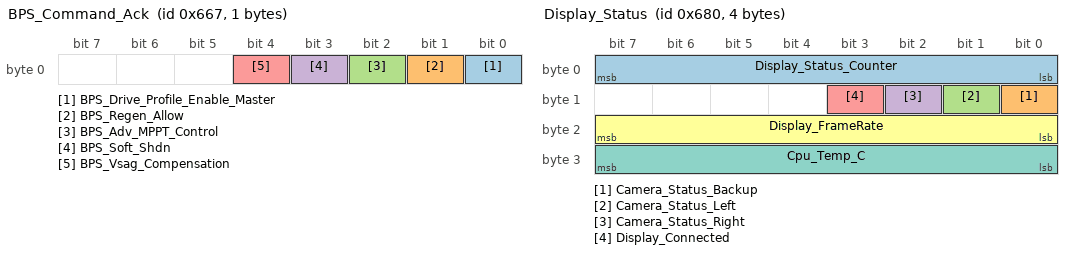
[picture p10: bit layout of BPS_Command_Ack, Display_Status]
BO_ 1639 BPS_Command_Ack: 1 BPS
SG_ BPS_Drive_Profile_Enable_Master : 0|1@1+ (1,0) [0|1] "" Vector__XXX
SG_ BPS_Regen_Allow : 1|1@1+ (1,0) [0|1] "" Vector__XXX
SG_ BPS_Adv_MPPT_Control : 2|1@1+ (1,0) [0|1] "" Vector__XXX
SG_ BPS_Soft_Shdn : 3|1@1+ (1,0) [0|1] "" Vector__XXX
SG_ BPS_Vsag_Compensation : 4|1@1+ (1,0) [0|1] "" Vector__XXX

CM_ "source=CarCAN" BO_ 1641;
BO_ 1641 BPS_Module_Override_Ack: 8 BPS
SG_ Module0_Override : 0|2@1+ (1,0) [0|3] "" Vector__XXX
SG_ Module1_Override : 2|2@1+ (1,0) [0|3] "" Vector__XXX
SG_ Module2_Override : 4|2@1+ (1,0) [0|3] "" Vector__XXX
SG_ Module3_Override : 6|2@1+ (1,0) [0|3] "" Vector__XXX
SG_ Module4_Override : 8|2@1+ (1,0) [0|3] "" Vector__XXX
SG_ Module5_Override : 10|2@1+ (1,0) [0|3] "" Vector__XXX
SG_ Module6_Override : 12|2@1+ (1,0) [0|3] "" Vector__XXX
SG_ Module7_Override : 14|2@1+ (1,0) [0|3] "" Vector__XXX
SG_ Module8_Override : 16|2@1+ (1,0) [0|3] "" Vector__XXX
SG_ Module9_Override : 18|2@1+ (1,0) [0|3] "" Vector__XXX
SG_ Module10_Override : 20|2@1+ (1,0) [0|3] "" Vector__XXX
SG_ Module11_Override : 22|2@1+ (1,0) [0|3] "" Vector__XXX
SG_ Module12_Override : 24|2@1+ (1,0) [0|3] "" Vector__XXX
SG_ Module13_Override : 26|2@1+ (1,0) [0|3] "" Vector__XXX
SG_ Module14_Override : 28|2@1+ (1,0) [0|3] "" Vector__XXX
SG_ Module15_Override : 30|2@1+ (1,0) [0|3] "" Vector__XXX
SG_ Module16_Override : 32|2@1+ (1,0) [0|3] "" Vector__XXX
SG_ Module17_Override : 34|2@1+ (1,0) [0|3] "" Vector__XXX
SG_ Module18_Override : 36|2@1+ (1,0) [0|3] "" Vector__XXX
SG_ Module19_Override : 38|2@1+ (1,0) [0|3] "" Vector__XXX
SG_ Module20_Override : 40|2@1+ (1,0) [0|3] "" Vector__XXX
SG_ Module21_Override : 42|2@1+ (1,0) [0|3] "" Vector__XXX
SG_ Module22_Override : 44|2@1+ (1,0) [0|3] "" Vector__XXX
SG_ Module23_Override : 46|2@1+ (1,0) [0|3] "" Vector__XXX
SG_ Module24_Override : 48|2@1+ (1,0) [0|3] "" Vector__XXX
SG_ Module25_Override : 50|2@1+ (1,0) [0|3] "" Vector__XXX
SG_ Module26_Override : 52|2@1+ (1,0) [0|3] "" Vector__XXX
SG_ Module27_Override : 54|2@1+ (1,0) [0|3] "" Vector__XXX
SG_ Module28_Override : 56|2@1+ (1,0) [0|3] "" Vector__XXX
SG_ Module29_Override : 58|2@1+ (1,0) [0|3] "" Vector__XXX
SG_ Module30_Override : 60|2@1+ (1,0) [0|3] "" Vector__XXX
SG_ Module31_Override : 62|2@1+ (1,0) [0|3] "" Vector__XXX

CM_ "source=CarCAN" BO_ 1664;
BO_ 1664 Display_Status: 4 Dashboard_Display
SG_ Display_Status_Counter : 0|8@1+ (1,0) [0|255] "" Vector__XXX
SG_ Camera_Status_Backup : 8|1@1+ (1,0) [0|1] "" Vector__XXX
SG_ Camera_Status_Left : 9|1@1+ (1,0) [0|1] "" Vector__XXX
SG_ Camera_Status_Right : 10|1@1+ (1,0) [0|1] "" Vector__XXX
SG_ Display_Connected : 11|1@1+ (1,0) [0|1] "" Vector__XXX
SG_ Display_FrameRate : 16|8@1+ (1,0) [0|255] "FPS" Vector__XXX
SG_ Cpu_Temp_C : 24|8@1+ (1,0) [0|255] "°C" Vector__XXX

CM_ "source=telem_rev1 (1)" BO_ 5888;
BO_ 5888 GPS_Latitude: 4 Vector__XXX
SG_ GPS_Latitude : 0|32@1+ (1,0) [0|4294967295] "" Vector__XXX

CM_ "source=telem_rev1 (1)" BO_ 5889;
BO_ 5889 GPS_Longitude: 4 Vector__XXX
SG_ GPS_Longitude : 0|32@1+ (1,0) [0|4294967295] "" Vector__XXX

CM_ "source=telem_rev1 (1)" BO_ 5890;
BO_ 5890 GPS_Speed: 2 Vector__XXX
SG_ GPS_Speed : 0|16@1+ (1,0) [0|65535] "" Vector__XXX

CM_ "source=telem_rev1 (1)" BO_ 5891;
BO_ 5891 GPS_Status: 1 Vector__XXX
SG_ GPS_Status : 0|8@1+ (1,0) [0|255] "" Vector__XXX

CM_ "source=CarCAN" BO_ 1872;
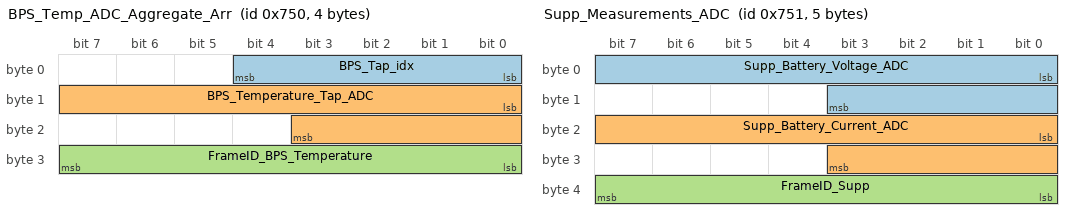
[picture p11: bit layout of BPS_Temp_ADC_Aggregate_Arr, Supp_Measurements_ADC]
BO_ 1872 BPS_Temp_ADC_Aggregate_Arr: 4 BPS
SG_ BPS_Tap_idx : 0|5@1+ (1,0) [0|31] "" Vector__XXX
SG_ BPS_Temperature_Tap_ADC : 8|12@1+ (1,0) [0|4095] "" Vector__XXX
SG_ FrameID_BPS_Temperature : 24|8@1+ (1,0) [0|255] "" Vector__XXX

CM_ "source=CarCAN" BO_ 1873;
BO_ 1873 Supp_Measurements_ADC: 5 LV_Carrier
SG_ Supp_Battery_Voltage_ADC : 0|12@1+ (1,0) [0|4095] "" Vector__XXX
SG_ Supp_Battery_Current_ADC : 16|12@1+ (1,0) [0|4095] "" Vector__XXX
SG_ FrameID_Supp : 32|8@1+ (1,0) [0|255] "" Vector__XXX

CM_ "source=CarCAN" BO_ 1874;
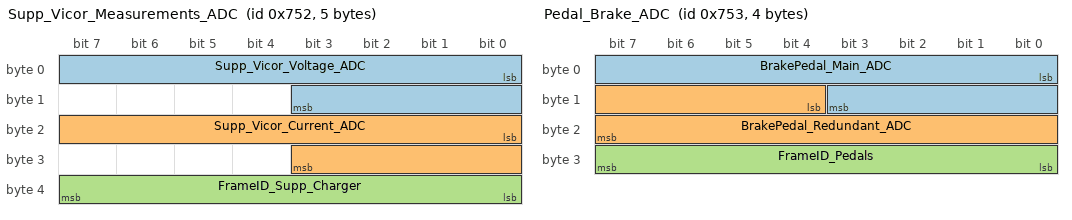
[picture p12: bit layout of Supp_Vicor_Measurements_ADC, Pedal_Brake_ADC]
BO_ 1874 Supp_Vicor_Measurements_ADC: 5 LV_Carrier
SG_ Supp_Vicor_Voltage_ADC : 0|12@1+ (1,0) [0|4095] "" Vector__XXX
SG_ Supp_Vicor_Current_ADC : 16|12@1+ (1,0) [0|4095] "" Vector__XXX
SG_ FrameID_Supp_Charger : 32|8@1+ (1,0) [0|255] "" Vector__XXX

CM_ "source=CarCAN" BO_ 1875;
BO_ 1875 Pedal_Brake_ADC: 4 Pedals
SG_ BrakePedal_Main_ADC : 0|12@1+ (1,0) [0|4095] "" Vector__XXX
SG_ BrakePedal_Redundant_ADC : 12|12@1+ (1,0) [0|4095] "" Vector__XXX
SG_ FrameID_Pedals : 24|8@1+ (1,0) [0|255] "" Vector__XXX

CM_ "source=CarCAN" BO_ 1876;
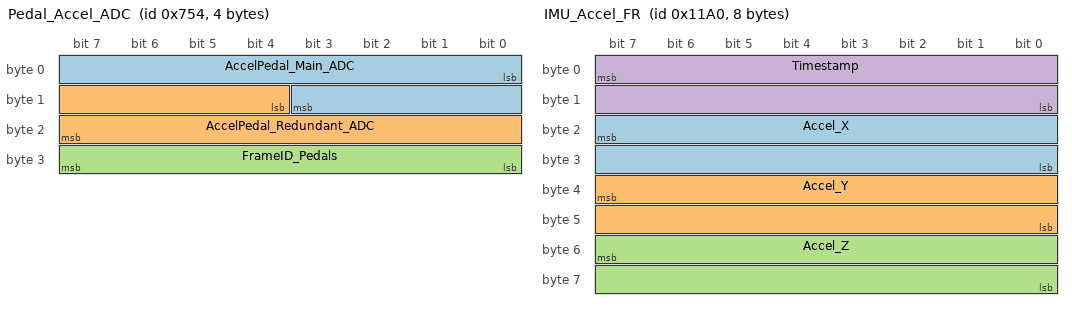
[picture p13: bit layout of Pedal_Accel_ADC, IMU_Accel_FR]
BO_ 1876 Pedal_Accel_ADC: 4 Pedals
SG_ AccelPedal_Main_ADC : 0|12@1+ (1,0) [0|4095] ""  VCU
SG_ AccelPedal_Redundant_ADC : 12|12@1+ (1,0) [0|4095] ""  VCU
SG_ FrameID_Pedals : 24|8@1+ (1,0) [0|255] "" Vector__XXX

CM_ "source=MotorCAN" BO_ 1953;
BO_ 1953 Set_Motor_Cmd_Src: 1 External
SG_ Motor_Command_Source : 0|1@1+ (1,0) [0|1] "" Vector__XXX

CM_ "source=SteeringCAN" BO_ 1984;
BO_ 1984 LWS_Config: 2 Controls
SG_ LWS_CCW : 0|4@1+ (1,0) [0|15] "" Vector__XXX
SG_ LWS_RES : 4|12@1+ (1,0) [0|4095] "" Vector__XXX

CM_ "source=telem_rev1 (1)" BO_ 4096;
BO_ 4096 TelemLeader_Center: 2 Vector__XXX
SG_ Timestamp : 0|16@1+ (1,0) [0|65535] "" Vector__XXX

CM_ "source=telem_rev1 (1)" BO_ 4512;
BO_ 4512 IMU_Accel_FR: 8 Vector__XXX
SG_ Accel_X : 23|16@0- (0.000122,0) [-3.997696|3.997574] "g" Vector__XXX
SG_ Accel_Y : 39|16@0- (0.000122,0) [-3.997696|3.997574] "g" Vector__XXX
SG_ Accel_Z : 55|16@0- (0.000122,0) [-3.997696|3.997574] "g" Vector__XXX
SG_ Timestamp : 7|16@0+ (1,0) [0|65535] "" Vector__XXX

CM_ "source=telem_rev1 (1)" BO_ 4513;
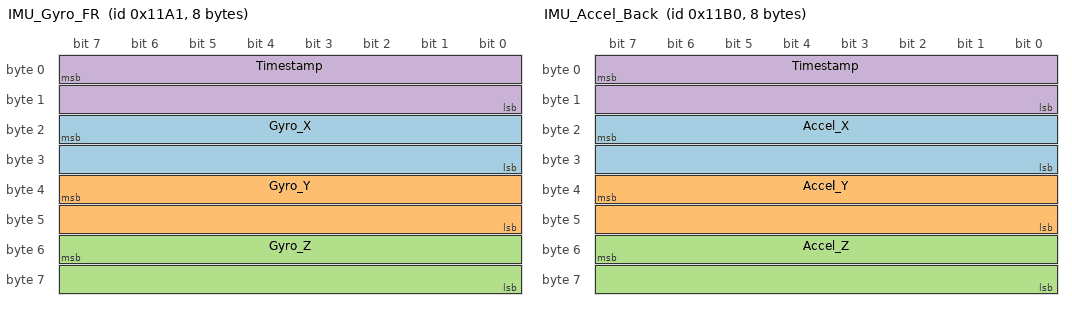
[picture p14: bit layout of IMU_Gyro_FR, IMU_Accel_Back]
BO_ 4513 IMU_Gyro_FR: 8 Vector__XXX
SG_ Gyro_X : 23|16@0- (0.00875,0) [-286.72|286.71125] "dps" Vector__XXX
SG_ Gyro_Y : 39|16@0- (0.00875,0) [-286.72|286.71125] "dps" Vector__XXX
SG_ Gyro_Z : 55|16@0- (0.00875,0) [-286.72|286.71125] "dps" Vector__XXX
SG_ Timestamp : 7|16@0+ (1,0) [0|65535] "" Vector__XXX

CM_ "source=telem_rev1 (1)" BO_ 4528;
BO_ 4528 IMU_Accel_Back: 8 Vector__XXX
SG_ Accel_X : 23|16@0- (0.000122,0) [-3.997696|3.997574] "g" Vector__XXX
SG_ Accel_Y : 39|16@0- (0.000122,0) [-3.997696|3.997574] "g" Vector__XXX
SG_ Accel_Z : 55|16@0- (0.000122,0) [-3.997696|3.997574] "g" Vector__XXX
SG_ Timestamp : 7|16@0+ (1,0) [0|65535] "" Vector__XXX

CM_ "source=telem_rev1 (1)" BO_ 4529;
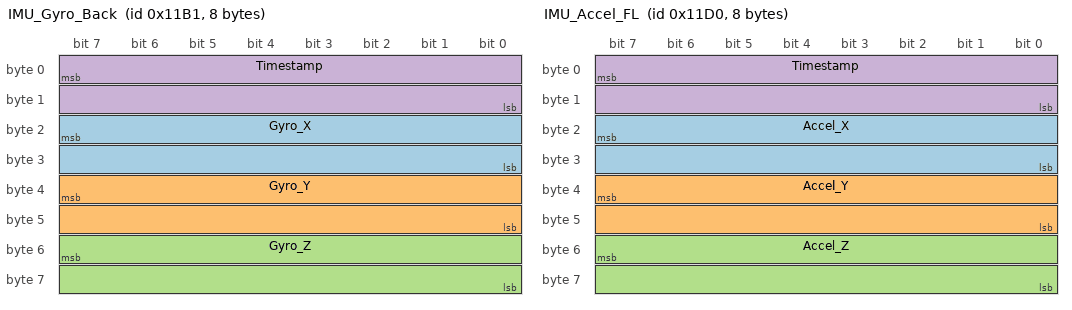
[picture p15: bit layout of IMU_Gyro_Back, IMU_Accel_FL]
BO_ 4529 IMU_Gyro_Back: 8 Vector__XXX
SG_ Gyro_X : 23|16@0- (0.00875,0) [-286.72|286.71125] "dps" Vector__XXX
SG_ Gyro_Y : 39|16@0- (0.00875,0) [-286.72|286.71125] "dps" Vector__XXX
SG_ Gyro_Z : 55|16@0- (0.00875,0) [-286.72|286.71125] "dps" Vector__XXX
SG_ Timestamp : 7|16@0+ (1,0) [0|65535] "" Vector__XXX

CM_ "source=telem_rev1 (1)" BO_ 4560;
BO_ 4560 IMU_Accel_FL: 8 Vector__XXX
SG_ Accel_X : 23|16@0- (0.000122,0) [-3.997696|3.997574] "g" Vector__XXX
SG_ Accel_Y : 39|16@0- (0.000122,0) [-3.997696|3.997574] "g" Vector__XXX
SG_ Accel_Z : 55|16@0- (0.000122,0) [-3.997696|3.997574] "g" Vector__XXX
SG_ Timestamp : 7|16@0+ (1,0) [0|65535] "" Vector__XXX

CM_ "source=telem_rev1 (1)" BO_ 4561;
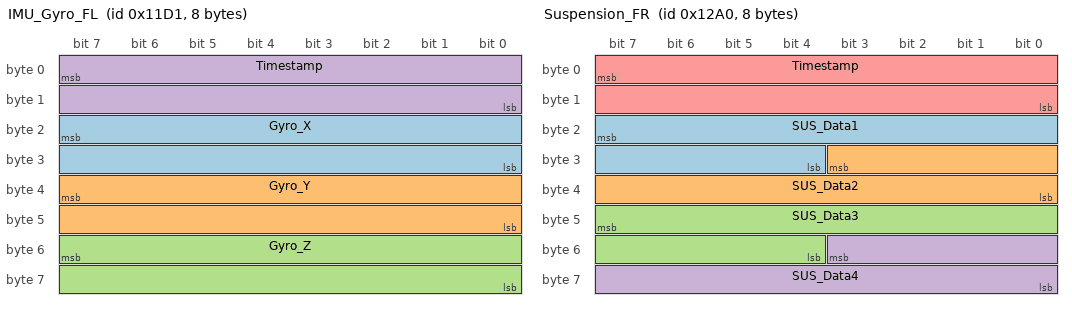
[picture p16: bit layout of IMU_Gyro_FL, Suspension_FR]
BO_ 4561 IMU_Gyro_FL: 8 Vector__XXX
SG_ Gyro_X : 23|16@0- (0.00875,0) [-286.72|286.71125] "dps" Vector__XXX
SG_ Gyro_Y : 39|16@0- (0.00875,0) [-286.72|286.71125] "dps" Vector__XXX
SG_ Gyro_Z : 55|16@0- (0.00875,0) [-286.72|286.71125] "dps" Vector__XXX
SG_ Timestamp : 7|16@0+ (1,0) [0|65535] "" Vector__XXX

CM_ "source=telem_rev1 (1)" BO_ 4768;
BO_ 4768 Suspension_FR: 8 Vector__XXX
SG_ SUS_Data1 : 23|12@0+ (1,0) [0|4095] "" Vector__XXX
SG_ SUS_Data2 : 27|12@0+ (1,0) [0|4095] "" Vector__XXX
SG_ SUS_Data3 : 47|12@0+ (1,0) [0|4095] "" Vector__XXX
SG_ SUS_Data4 : 51|12@0+ (1,0) [0|4095] "" Vector__XXX
SG_ Timestamp : 7|16@0+ (1,0) [0|65535] "" Vector__XXX

CM_ "source=telem_rev1 (1)" BO_ 4784;
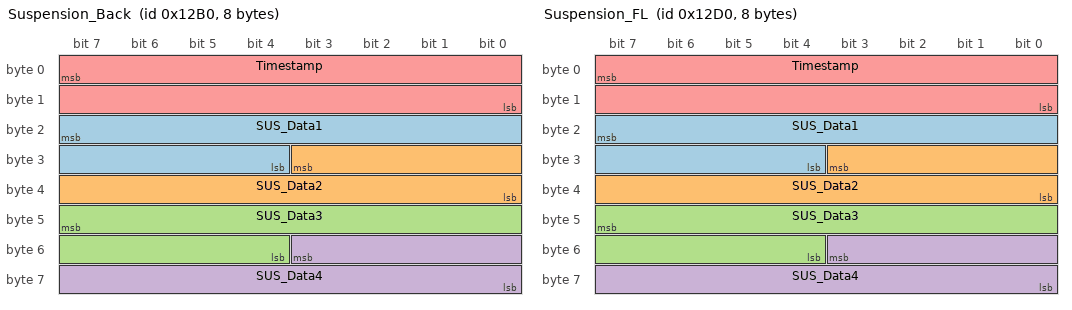
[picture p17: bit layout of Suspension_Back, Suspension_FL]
BO_ 4784 Suspension_Back: 8 Vector__XXX
SG_ SUS_Data1 : 23|12@0+ (1,0) [0|4095] "" Vector__XXX
SG_ SUS_Data2 : 27|12@0+ (1,0) [0|4095] "" Vector__XXX
SG_ SUS_Data3 : 47|12@0+ (1,0) [0|4095] "" Vector__XXX
SG_ SUS_Data4 : 51|12@0+ (1,0) [0|4095] "" Vector__XXX
SG_ Timestamp : 7|16@0+ (1,0) [0|65535] "" Vector__XXX

CM_ "source=telem_rev1 (1)" BO_ 4816;
BO_ 4816 Suspension_FL: 8 Vector__XXX
SG_ SUS_Data1 : 23|12@0+ (1,0) [0|4095] "" Vector__XXX
SG_ SUS_Data2 : 27|12@0+ (1,0) [0|4095] "" Vector__XXX
SG_ SUS_Data3 : 47|12@0+ (1,0) [0|4095] "" Vector__XXX
SG_ SUS_Data4 : 51|12@0+ (1,0) [0|4095] "" Vector__XXX
SG_ Timestamp : 7|16@0+ (1,0) [0|65535] "" Vector__XXX

CM_ "source=telem_rev1 (1)" BO_ 5024;
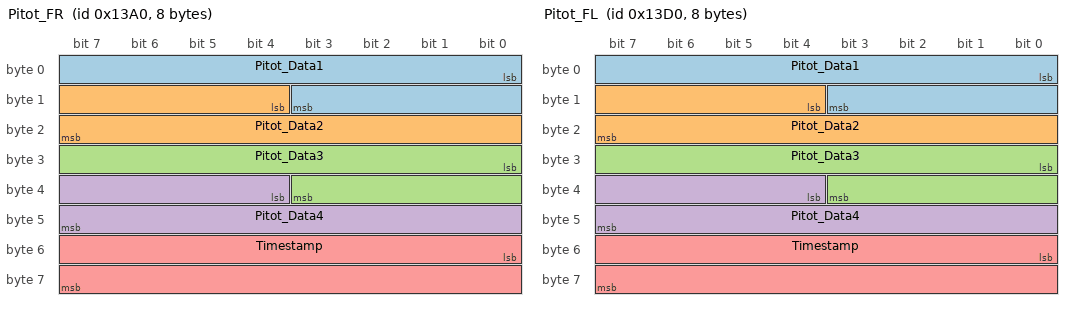
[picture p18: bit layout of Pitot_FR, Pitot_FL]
BO_ 5024 Pitot_FR: 8 Vector__XXX
SG_ Pitot_Data1 : 0|12@1+ (1,0) [0|4095] "" Vector__XXX
SG_ Pitot_Data2 : 12|12@1+ (1,0) [0|4095] "" Vector__XXX
SG_ Pitot_Data3 : 24|12@1+ (1,0) [0|4095] "" Vector__XXX
SG_ Pitot_Data4 : 36|12@1+ (1,0) [0|4095] "" Vector__XXX
SG_ Timestamp : 48|16@1+ (1,0) [0|65535] "" Vector__XXX

CM_ "source=telem_rev1 (1)" BO_ 5072;
BO_ 5072 Pitot_FL: 8 Vector__XXX
SG_ Pitot_Data1 : 0|12@1+ (1,0) [0|4095] "" Vector__XXX
SG_ Pitot_Data2 : 12|12@1+ (1,0) [0|4095] "" Vector__XXX
SG_ Pitot_Data3 : 24|12@1+ (1,0) [0|4095] "" Vector__XXX
SG_ Pitot_Data4 : 36|12@1+ (1,0) [0|4095] "" Vector__XXX
SG_ Timestamp : 48|16@1+ (1,0) [0|65535] "" Vector__XXX

CM_ "source=telem_rev1 (1)" BO_ 5124;
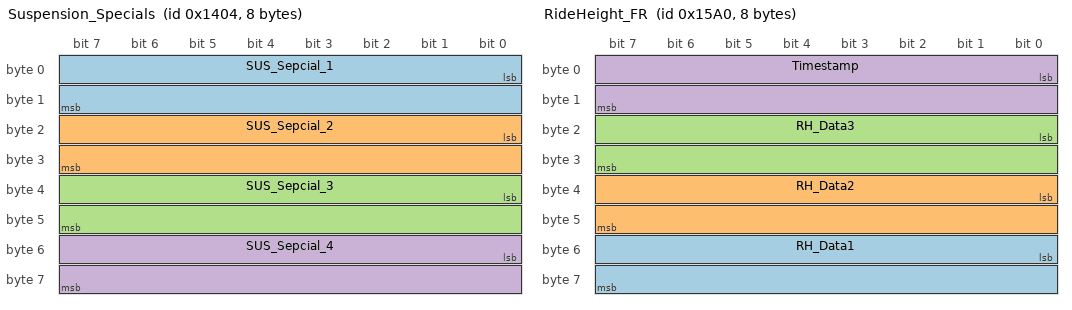
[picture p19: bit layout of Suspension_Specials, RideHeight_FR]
BO_ 5124 Suspension_Specials: 8 Vector__XXX
SG_ SUS_Sepcial_1 : 0|16@1+ (1,0) [0|65535] "" Vector__XXX
SG_ SUS_Sepcial_2 : 16|16@1+ (1,0) [0|65535] "" Vector__XXX
SG_ SUS_Sepcial_3 : 32|16@1+ (1,0) [0|65535] "" Vector__XXX
SG_ SUS_Sepcial_4 : 48|16@1+ (1,0) [0|65535] "" Vector__XXX

CM_ "source=telem_rev1 (1)" BO_ 5280;
BO_ 5280 WheelRPM_FR: 8 Vector__XXX
SG_ RPM : 0|16@1+ (1,0) [0|65535] "rpm" Vector__XXX
SG_ Timestamp : 16|16@1+ (1,0) [0|65535] "" Vector__XXX

CM_ "source=telem_rev1 (1)" BO_ 5328;
BO_ 5328 WheelRPM_FL: 8 Vector__XXX
SG_ RPM : 0|16@1+ (1,0) [0|65535] "rpm" Vector__XXX
SG_ Timestamp : 16|16@1+ (1,0) [0|65535] "" Vector__XXX

CM_ "source=telem_rev1 (1)" BO_ 5536;
BO_ 5536 RideHeight_FR: 8 Vector__XXX
SG_ RH_Data1 : 48|16@1+ (1,0) [0|65535] "" Vector__XXX
SG_ RH_Data2 : 32|16@1+ (1,0) [0|65535] "" Vector__XXX
SG_ RH_Data3 : 16|16@1+ (1,0) [0|65535] "" Vector__XXX
SG_ Timestamp : 0|16@1+ (1,0) [0|65535] "" Vector__XXX

CM_ "source=telem_rev1 (1)" BO_ 5552;
BO_ 5552 RideHeight_Back: 8 Vector__XXX
SG_ RH_Data1 : 48|16@1+ (1,0) [0|65535] "" Vector__XXX
SG_ RH_Data2 : 32|16@1+ (1,0) [0|65535] "" Vector__XXX
SG_ RH_Data3 : 16|16@1+ (1,0) [0|65535] "" Vector__XXX
SG_ Timestamp : 0|16@1+ (1,0) [0|65535] "" Vector__XXX

CM_ "source=telem_rev1 (1)" BO_ 5584;
BO_ 5584 RideHeight_FL: 8 Vector__XXX
SG_ RH_Data1 : 48|16@1+ (1,0) [0|65535] "" Vector__XXX
SG_ RH_Data2 : 32|16@1+ (1,0) [0|65535] "" Vector__XXX
SG_ RH_Data3 : 16|16@1+ (1,0) [0|65535] "" Vector__XXX
SG_ Timestamp : 0|16@1+ (1,0) [0|65535] "" Vector__XXX

CM_ "source=telem_rev1 (1)" BO_ 6080;
BO_ 6080 Temp_1_Center: 8 Vector__XXX
SG_ Temperature : 0|16@1+ (1,0) [0|65535] "" Vector__XXX
SG_ Humidity : 16|16@1+ (1,0) [0|65535] "" Vector__XXX
SG_ Timestamp : 32|16@1+ (1,0) [0|65535] "" Vector__XXX

CM_ "source=telem_rev1 (1)" BO_ 6081;
BO_ 6081 Temp_2_Center: 8 Vector__XXX
SG_ Temperature : 0|16@1+ (1,0) [0|65535] "" Vector__XXX
SG_ Humidity : 16|16@1+ (1,0) [0|65535] "" Vector__XXX
SG_ Timestamp : 32|16@1+ (1,0) [0|65535] "" Vector__XXX

SIG_VALTYPE_;
SIG_VALTYPE_ 1025 MC_MotorVelocitySetpoint : 1;
SIG_VALTYPE_ 1025 MC_MotorCurrentSetpoint : 1;
SIG_VALTYPE_ 1026 MC_MotorPowerSetpoint : 1;
SIG_VALTYPE_ 1058 MC_BusVoltage : 1;
SIG_VALTYPE_ 1058 MC_BusCurrent : 1;
SIG_VALTYPE_ 1059 MC_MotorVelocity : 1;
SIG_VALTYPE_ 1059 MC_VehicleVelocity : 1;
SIG_VALTYPE_ 1060 MC_PhaseCurrentB : 1;
SIG_VALTYPE_ 1060 MC_PhaseCurrentC : 1;
SIG_VALTYPE_ 1061 MC_Vq : 1;
SIG_VALTYPE_ 1061 MC_Vd : 1;
SIG_VALTYPE_ 1062 MC_Iq : 1;
SIG_VALTYPE_ 1062 MC_Id : 1;
SIG_VALTYPE_ 1063 MC_BEMFq : 1;
SIG_VALTYPE_ 1063 MC_BEMFd : 1;
SIG_VALTYPE_ 1064 MC_Supply15V : 1;
SIG_VALTYPE_ 1065 MC_Supply1V9 : 1;
SIG_VALTYPE_ 1065 MC_Supply3V3 : 1;
SIG_VALTYPE_ 1067 MC_MotorTemp : 1;
SIG_VALTYPE_ 1067 MC_HeatsinkTemp : 1;
SIG_VALTYPE_ 1068 MC_DspBoardTemp : 1;
SIG_VALTYPE_ 1070 MC_TripOdometer : 1;
SIG_VALTYPE_ 1070 MC_DCBusAh : 1;
SIG_VALTYPE_ 1079 MC_SlipSpeed : 1;
